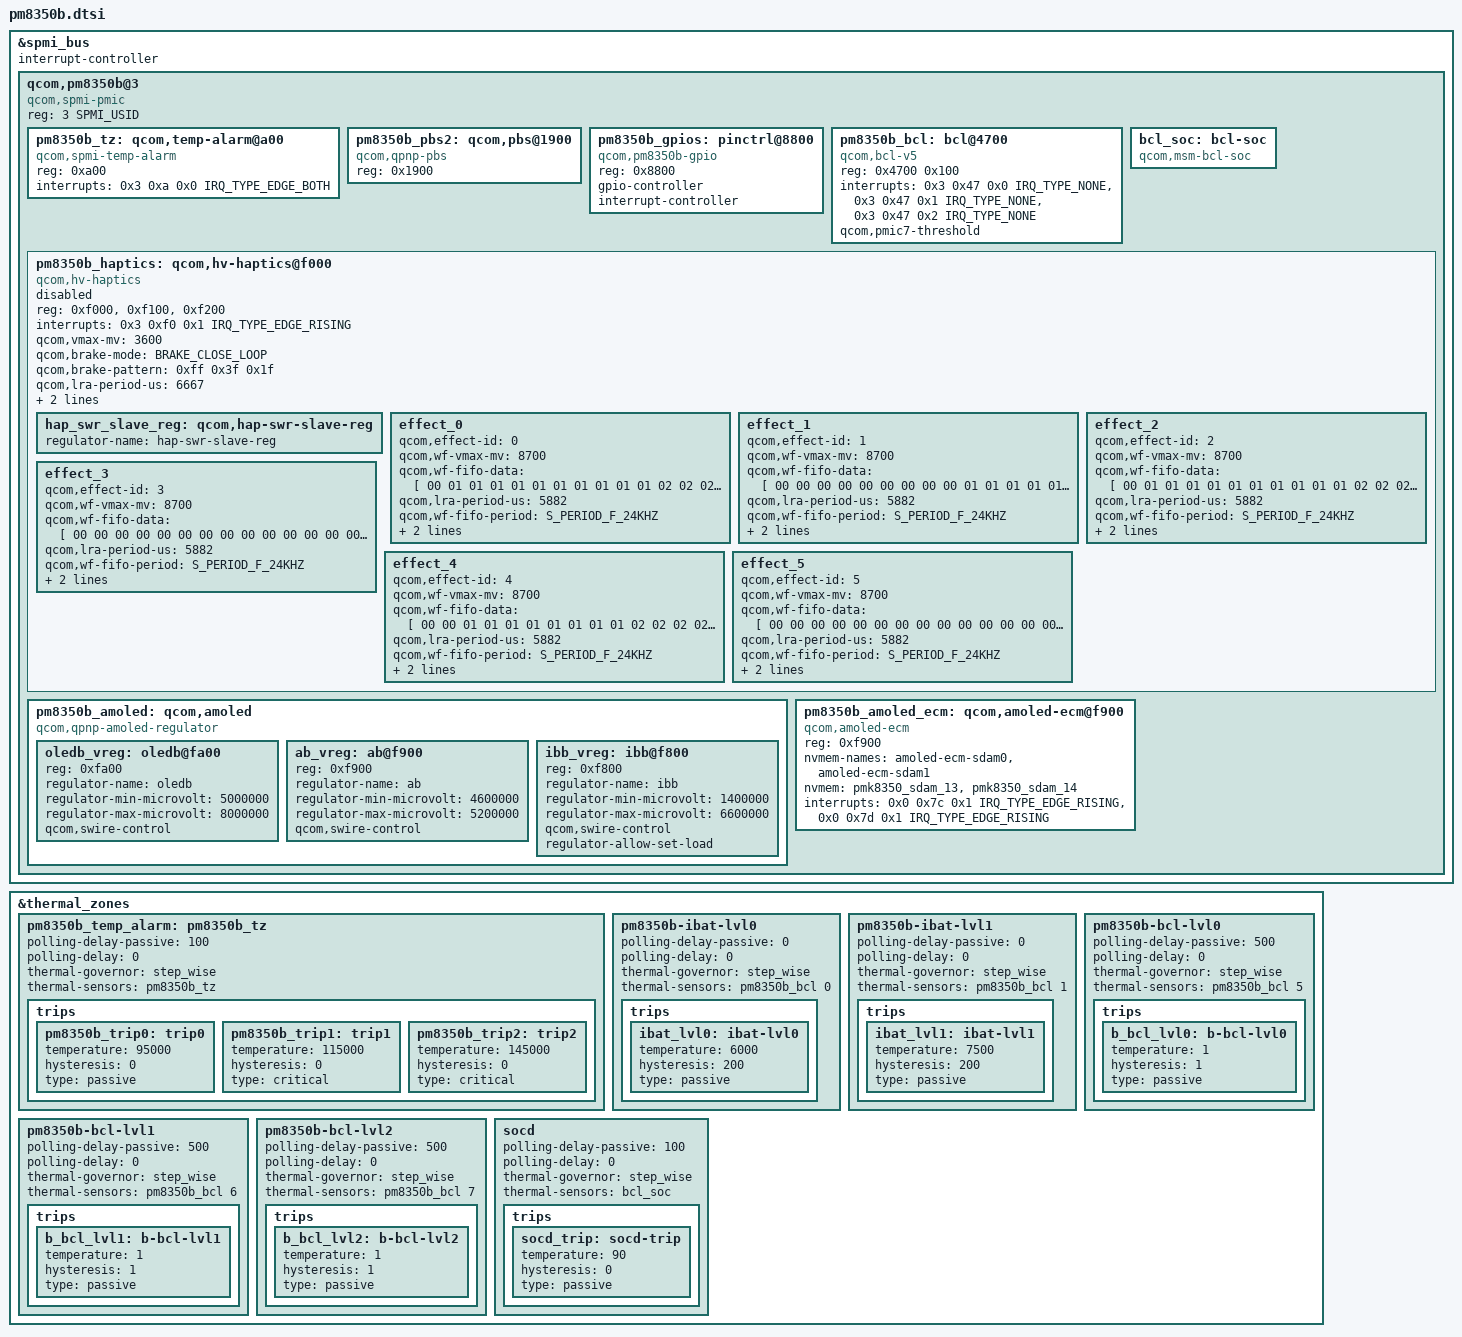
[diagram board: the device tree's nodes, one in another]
#include <dt-bindings/interrupt-controller/irq.h>
#include <dt-bindings/spmi/spmi.h>
#include <dt-bindings/input/qcom,hv-haptics.h>

&spmi_bus {
	#address-cells = <2>;
	#size-cells = <0>;
	interrupt-controller;
	#interrupt-cells = <4>;

	qcom,pm8350b@3 {
		compatible = "qcom,spmi-pmic";
		reg = <3 SPMI_USID>;
		#address-cells = <1>;
		#size-cells = <0>;

		pm8350b_tz: qcom,temp-alarm@a00 {
			compatible = "qcom,spmi-temp-alarm";
			reg = <0xa00>;
			interrupts = <0x3 0xa 0x0 IRQ_TYPE_EDGE_BOTH>;
			#thermal-sensor-cells = <0>;
		};

		pm8350b_pbs2: qcom,pbs@1900 {
			compatible = "qcom,qpnp-pbs";
			reg = <0x1900>;
		};

		pm8350b_gpios: pinctrl@8800 {
			compatible = "qcom,pm8350b-gpio";
			reg = <0x8800>;
			gpio-controller;
			#gpio-cells = <2>;
			interrupt-controller;
			#interrupt-cells = <2>;
		};

		pm8350b_bcl: bcl@4700 {
			compatible = "qcom,bcl-v5";
			reg = <0x4700 0x100>;
			interrupts = <0x3 0x47 0x0 IRQ_TYPE_NONE>,
					<0x3 0x47 0x1 IRQ_TYPE_NONE>,
					<0x3 0x47 0x2 IRQ_TYPE_NONE>;
			interrupt-names = "bcl-lvl0",
						"bcl-lvl1",
						"bcl-lvl2";
			qcom,pmic7-threshold;
			#thermal-sensor-cells = <1>;
		};

		bcl_soc:bcl-soc {
			compatible = "qcom,msm-bcl-soc";
			#thermal-sensor-cells = <0>;
		};

		pm8350b_haptics: qcom,hv-haptics@f000 {
			compatible = "qcom,hv-haptics";
			reg = <0xf000>, <0xf100>, <0xf200>;
			interrupts = <0x3 0xf0 0x1 IRQ_TYPE_EDGE_RISING>;
			interrupt-names = "fifo-empty";
			qcom,vmax-mv = <3600>;
			qcom,brake-mode = <BRAKE_CLOSE_LOOP>;
			qcom,brake-pattern = /bits/ 8 <0xff 0x3f 0x1f>;
			qcom,lra-period-us = <6667>;
			qcom,drv-sig-shape = <WF_SINE>;
			qcom,brake-sig-shape = <WF_SINE>;
			status = "disabled";

			hap_swr_slave_reg: qcom,hap-swr-slave-reg {
				regulator-name = "hap-swr-slave-reg";
			};

			effect_0 {
				/* CLICK */
				qcom,effect-id = <0>;
				qcom,wf-vmax-mv = <8700>;
				qcom,wf-fifo-data = [
								    00 01 01 01 01 01 01 01
				                                    01 01 01 02 02 02 02 02
				                                    03 03 03 04 04 04 05 05
				                                    05 06 06 07 08 08 09 0a
				                                    0b 0c 0d 0e 0f 10 11 13
				                                    14 16 18 1a 1c 1e 21 24
				                                    27 2a 2d 31 35 39 3e 43
				                                    49 4f 55 5c 64 6b 71 76
				                                    7a 7d 7f 7f 7f 7f 7d 7b
				                                    78 74 70 6b 65 60 59 53
				                                    4c 45 3d 36 2e 26 1e 16
				                                    0f 07 00 f8 f0 e9 e1 da
				                                    d4 cd c6 c0 ba b3 ae a9
				                                    a6 a4 a3 a3 a5 a8 ab b0
				                                    b6 bc c3 cb d4 dd e6 f0
				                                    fa 04 0f 19 24 2e 38 41
				                                    4a 53 5b 62 69 6e 73 77
				                                    79 7b 7b 7a 78 74 6f 68
				                                    60 59 52 4b 44 3d 36 30
				                                    29 22 1b 14 0e 07 00 fa
				                                    f3 ed e6 e0 da d4 cf ca
				                                    c5 c0 bc b8 b5 b2 af ad
				                                    ac ac ac ac ae b0 b3 b6
				                                    bb c0 c5 ca ce d2 d6 d9
				                                    dc df e2 e4 e7 e9 ea ec
				                                    ee ef f1 f2 f3 f4 f5 f6
				                                    f7 f7 f8 f9 f9 fa fa fb
				                                    fb fb fc fc fc fd fd fd
				                                    fd fd fd fe fe fe fe fe
				                                    fe fe fe fe fe fe fe 00
				                                    00 00 00 00 00 00 00 00
				                                    00 00 00 00 00 00 00 00
				                                    00 00 00 00 00 00 00 00 ];
				qcom,lra-period-us = <5882>;
				qcom,wf-fifo-period = <S_PERIOD_F_24KHZ>;
				qcom,wf-brake-disable;
				qcom,wf-auto-res-disable;
			};

			effect_1 {
				/* DOUBLE_CLICK */
				qcom,effect-id = <1>;
				qcom,wf-vmax-mv = <8700>;
				qcom,wf-fifo-data = [
								    00 00 00 00 00 00 00 00
				                                    00 01 01 01 01 01 01 01
				                                    01 01 02 02 02 02 02 03
				                                    03 03 03 04 04 05 05 05
				                                    06 06 07 08 08 09 0a 0b
				                                    0b 0c 0d 0f 10 11 12 13
				                                    13 13 13 13 13 12 12 11
				                                    10 0e 0d 0c 0a 08 06 04
				                                    02 00 fd fb f8 f5 f2 ef
				                                    ec e9 e5 e2 de da d6 d2
				                                    cd c9 c4 be b9 b3 ad a8
				                                    a5 a3 a2 a3 a4 a7 ab af
				                                    b5 bc c3 cb d4 dd e7 f1
				                                    fb 06 10 1b 26 30 3a 44
				                                    4d 56 5e 66 6c 72 77 7b
				                                    7e 7f 7f 7f 7c 78 73 6c
				                                    65 5e 57 50 49 42 3b 34
				                                    2e 27 20 1a 13 0d 07 00
				                                    fa f4 ee e9 e4 de da d5
				                                    d1 ce cb c8 c6 c4 c4 c3
				                                    c4 c5 c8 cb cf d4 da e1
				                                    e9 f2 fb 02 0a 10 16 1c
				                                    21 25 29 2c 30 32 35 37
				                                    38 3a 3b 3c 3d 3d 3d 3e
				                                    3d 3d 3d 3c 3c 3b 3a 39
				                                    38 37 36 35 33 32 31 2f
				                                    2e 2c 2b 29 28 26 25 23
				                                    22 20 1f 1e 1c 1b 19 18
				                                    17 15 14 13 12 11 0f 0e
				                                    0d 0c 0b 0a 09 08 07 07
				                                    06 05 04 04 03 02 02 01
				                                    00 00 00 00 00 fe fe fd
				                                    fd fd fc fc fc fc fb fb
				                                    fb fb fb fb fb fb fa fa
				                                    fa fa fa fa fa fa fa fa
				                                    fa fa fb fb fb fb fb fb
				                                    fb fb fb fb fb fb fc fc
				                                    fc fc fc fc fc fc fc fd
				                                    fd fd fd fd fd fd fd fd
				                                    fd fe fe fe fe fe fe fe
				                                    fe fe fe fe 00 00 00 00 ];
				qcom,lra-period-us = <5882>;
				qcom,wf-fifo-period = <S_PERIOD_F_24KHZ>;
				qcom,wf-brake-disable;
				qcom,wf-auto-res-disable;
			};

			effect_2 {
				/* TICK */
				qcom,effect-id = <2>;
				qcom,wf-vmax-mv = <8700>;
				qcom,wf-fifo-data = [
								    00 01 01 01 01 01 01 01
				                                    01 01 01 02 02 02 02 02
				                                    03 03 03 04 04 04 05 05
				                                    05 06 06 07 08 08 09 0a
				                                    0b 0c 0d 0e 0f 10 11 13
				                                    14 16 18 1a 1c 1e 21 24
				                                    27 2a 2d 31 35 39 3e 43
				                                    49 4f 55 5c 64 6b 71 76
				                                    7a 7d 7f 7f 7f 7f 7d 7b
				                                    78 74 70 6b 65 60 59 53
				                                    4c 45 3d 36 2e 26 1e 16
				                                    0f 07 00 f8 f0 e9 e1 da
				                                    d4 cd c6 c0 ba b3 ae a9
				                                    a6 a4 a3 a3 a5 a8 ab b0
				                                    b6 bc c3 cb d4 dd e6 f0
				                                    fa 04 0f 19 24 2e 38 41
				                                    4a 53 5b 62 69 6e 73 77
				                                    79 7b 7b 7a 78 74 6f 68
				                                    60 59 52 4b 44 3d 36 30
				                                    29 22 1b 14 0e 07 00 fa
				                                    f3 ed e6 e0 da d4 cf ca
				                                    c5 c0 bc b8 b5 b2 af ad
				                                    ac ac ac ac ae b0 b3 b6
				                                    bb c0 c5 ca ce d2 d6 d9
				                                    dc df e2 e4 e7 e9 ea ec
				                                    ee ef f1 f2 f3 f4 f5 f6
				                                    f7 f7 f8 f9 f9 fa fa fb
				                                    fb fb fc fc fc fd fd fd
				                                    fd fd fd fe fe fe fe fe
				                                    fe fe fe fe fe fe fe 00
				                                    00 00 00 00 00 00 00 00
				                                    00 00 00 00 00 00 00 00
				                                    00 00 00 00 00 00 00 00 ];
				qcom,lra-period-us = <5882>;
				qcom,wf-fifo-period = <S_PERIOD_F_24KHZ>;
				qcom,wf-brake-disable;
				qcom,wf-auto-res-disable;
			};

			effect_3 {
				/* THUD */
				qcom,effect-id = <3>;
				qcom,wf-vmax-mv = <8700>;
				qcom,wf-fifo-data = [
								    00 00 00 00 00 00 00 00
				                                    00 00 00 00 00 00 00 00
				                                    00 00 00 00 00 00 00 00
				                                    00 00 00 00 01 01 01 01
				                                    01 01 02 02 02 03 03 04
				                                    04 05 06 07 08 09 0a 0c
				                                    0e 10 12 14 17 1b 1e 23
				                                    28 2d 34 3b 43 4b 52 58
				                                    5d 61 64 66 68 6a 6a 6b
				                                    6a 6a 69 68 66 65 62 60
				                                    5e 5b 58 56 53 4f 4c 49
				                                    45 42 3e 3b 37 33 2f 2c
				                                    28 24 1f 1b 17 12 0d 08
				                                    03 fc f6 ef e8 e0 d7 cd
				                                    c2 b7 ad a5 9f 9a 96 93
				                                    92 91 91 93 94 97 9a 9e
				                                    a2 a7 ac b1 b7 bd c4 ca
				                                    d1 d8 df e6 ee f5 fc 04
				                                    0b 12 19 20 26 2d 33 39
				                                    3f 45 4a 4f 54 59 5e 62
				                                    66 6a 6e 72 75 79 7c 7e
				                                    7f 7f 7f 7e 7c 7a 77 73
				                                    6f 6a 65 5f 59 53 4c 45
				                                    3e 37 2f 27 1f 17 0f 07
				                                    fe f6 ee e6 df d7 d0 c9
				                                    c2 bc b6 b1 ac a7 a3 a0
				                                    9d 9b 99 99 99 9a 9c 9e
				                                    a2 a8 ad b2 b7 bc c1 c5
				                                    ca cf d3 d8 dd e2 e7 ec
				                                    f2 f7 fd 03 09 0f 14 1a
				                                    20 26 2c 32 37 3d 42 48
				                                    4d 52 57 5b 5f 63 67 6a
				                                    6c 6e 70 71 71 71 6f 6d
				                                    6a 66 61 5a 52 49 3f 35
				                                    2d 26 1f 1a 14 0f 0b 07
				                                    03 00 fb f8 f5 f3 f0 ed
				                                    eb e9 e6 e4 e2 e0 de dc
				                                    da d8 d6 d5 d3 d1 d0 cf
				                                    cd cc cb cb ca ca c9 c9
				                                    ca ca cb cc cd cf d2 d4
				                                    d8 dc e0 e4 e8 eb ee f0
				                                    f2 f4 f5 f7 f8 f9 fa fb
				                                    fb fc fd fd fd fe fe fe
				                                    fe 00 00 00 00 00 00 00
				                                    00 00 00 00 00 00 00 00
				                                    00 00 00 00 00 00 00 00
				                                    00 00 00 00 00 00 00 00 ];
				qcom,lra-period-us = <5882>;
				qcom,wf-fifo-period = <S_PERIOD_F_24KHZ>;
				qcom,wf-brake-disable;
				qcom,wf-auto-res-disable;
			};

			effect_4 {
				/* POP */
				qcom,effect-id = <4>;
				qcom,wf-vmax-mv = <8700>;
				qcom,wf-fifo-data = [
								    00 00 01 01 01 01 01 01
				                                    01 01 02 02 02 02 02 02
				                                    03 03 03 04 04 04 05 05
				                                    06 06 07 07 08 08 09 0a
				                                    0b 0c 0d 0e 0f 10 12 13
				                                    15 17 18 1b 1d 1f 22 24
				                                    27 2b 2e 32 36 3b 40 45
				                                    4a 51 57 5e 65 6b 70 75
				                                    78 7b 7d 7f 7f 7f 7f 7e
				                                    7d 7b 78 76 72 6f 6b 67
				                                    63 5e 59 54 4f 4a 44 3f
				                                    39 33 2e 28 22 1d 17 11
				                                    0c 06 01 fb f6 f0 eb e5
				                                    e0 da d5 cf cb c8 c6 c4
				                                    c3 c4 c5 c6 c9 cc cf d3
				                                    d8 dd e3 e9 ef f5 fc 03
				                                    0a 11 18 1f 26 2d 34 3a
				                                    40 46 4b 50 55 59 5c 5e
				                                    60 61 62 61 60 5e 5b 56
				                                    51 4b 44 3d 37 31 2b 25
				                                    20 1a 15 0f 0a 05 00 fa
				                                    f5 f1 ec e7 e2 de d9 d5
				                                    d0 cc c8 c4 c1 bd ba b7
				                                    b5 b2 b0 af ad ac ac ac
				                                    ac ad ae af b2 b5 b8 bc
				                                    c1 c6 ca cf d2 d6 d9 dc
				                                    df e2 e4 e6 e8 ea ec ed
				                                    ef f0 f1 f2 f3 f4 f5 f6
				                                    f7 f7 f8 f9 f9 f9 fa fa
				                                    fb fb fb fc fc fc fc fc
				                                    fd fd fd fd fd fd fd fe
				                                    fe fe fe fe fe fe fe fe
				                                    fe fe fe fe fe fe fe fe
				                                    fe 00 00 00 00 00 00 00
				                                    00 00 00 00 00 00 00 00 ];
				qcom,lra-period-us = <5882>;
				qcom,wf-fifo-period = <S_PERIOD_F_24KHZ>;
				qcom,wf-brake-disable;
				qcom,wf-auto-res-disable;
			};

			effect_5 {
				/* HEAVY CLICK */
				qcom,effect-id = <5>;
				qcom,wf-vmax-mv = <8700>;
				qcom,wf-fifo-data = [
								    00 00 00 00 00 00 00 00
				                                    00 00 00 00 00 00 00 00
				                                    00 00 00 00 00 00 00 00
				                                    00 00 00 00 01 01 01 01
				                                    01 01 02 02 02 03 03 04
				                                    04 05 06 07 08 09 0a 0c
				                                    0e 10 12 14 17 1b 1e 23
				                                    28 2d 34 3b 43 4b 52 58
				                                    5d 61 64 66 68 6a 6a 6b
				                                    6a 6a 69 68 66 65 62 60
				                                    5e 5b 58 56 53 4f 4c 49
				                                    45 42 3e 3b 37 33 2f 2c
				                                    28 24 1f 1b 17 12 0d 08
				                                    03 fc f6 ef e8 e0 d7 cd
				                                    c2 b7 ad a5 9f 9a 96 93
				                                    92 91 91 93 94 97 9a 9e
				                                    a2 a7 ac b1 b7 bd c4 ca
				                                    d1 d8 df e6 ee f5 fc 04
				                                    0b 12 19 20 26 2d 33 39
				                                    3f 45 4a 4f 54 59 5e 62
				                                    66 6a 6e 72 75 79 7c 7e
				                                    7f 7f 7f 7e 7c 7a 77 73
				                                    6f 6a 65 5f 59 53 4c 45
				                                    3e 37 2f 27 1f 17 0f 07
				                                    fe f6 ee e6 df d7 d0 c9
				                                    c2 bc b6 b1 ac a7 a3 a0
				                                    9d 9b 99 99 99 9a 9c 9e
				                                    a2 a8 ad b2 b7 bc c1 c5
				                                    ca cf d3 d8 dd e2 e7 ec
				                                    f2 f7 fd 03 09 0f 14 1a
				                                    20 26 2c 32 37 3d 42 48
				                                    4d 52 57 5b 5f 63 67 6a
				                                    6c 6e 70 71 71 71 6f 6d
				                                    6a 66 61 5a 52 49 3f 35
				                                    2d 26 1f 1a 14 0f 0b 07
				                                    03 00 fb f8 f5 f3 f0 ed
				                                    eb e9 e6 e4 e2 e0 de dc
				                                    da d8 d6 d5 d3 d1 d0 cf
				                                    cd cc cb cb ca ca c9 c9
				                                    ca ca cb cc cd cf d2 d4
				                                    d8 dc e0 e4 e8 eb ee f0
				                                    f2 f4 f5 f7 f8 f9 fa fb
				                                    fb fc fd fd fd fe fe fe
				                                    fe 00 00 00 00 00 00 00
				                                    00 00 00 00 00 00 00 00
				                                    00 00 00 00 00 00 00 00
				                                    00 00 00 00 00 00 00 00 ];
				qcom,lra-period-us = <5882>;
				qcom,wf-fifo-period = <S_PERIOD_F_24KHZ>;
				qcom,wf-brake-disable;
				qcom,wf-auto-res-disable;
			};
		};

		pm8350b_amoled: qcom,amoled {
			compatible = "qcom,qpnp-amoled-regulator";
			#address-cells = <1>;
			#size-cells = <0>;

			oledb_vreg: oledb@fa00 {
				reg = <0xfa00>;
				reg-names = "oledb_base";
				regulator-name = "oledb";
				regulator-min-microvolt = <5000000>;
				regulator-max-microvolt = <8000000>;
				qcom,swire-control;
			};

			ab_vreg: ab@f900 {
				reg = <0xf900>;
				reg-names = "ab_base";
				regulator-name = "ab";
				regulator-min-microvolt = <4600000>;
				regulator-max-microvolt = <5200000>;
				qcom,swire-control;
			};

			ibb_vreg: ibb@f800 {
				reg = <0xf800>;
				reg-names = "ibb_base";
				regulator-name = "ibb";
				regulator-min-microvolt = <1400000>;
				regulator-max-microvolt = <6600000>;
				qcom,swire-control;
				regulator-allow-set-load;
			};
		};

		pm8350b_amoled_ecm: qcom,amoled-ecm@f900 {
			compatible = "qcom,amoled-ecm";
			reg = <0xf900>;
			nvmem-names = "amoled-ecm-sdam0", "amoled-ecm-sdam1";
			nvmem = <&pmk8350_sdam_13>, <&pmk8350_sdam_14>;
			interrupt-names = "ecm-sdam0", "ecm-sdam1";
			interrupts = <0x0 0x7c 0x1 IRQ_TYPE_EDGE_RISING>,
				     <0x0 0x7d 0x1 IRQ_TYPE_EDGE_RISING>;
		};
	};
};

&thermal_zones {
	pm8350b_temp_alarm: pm8350b_tz {
		polling-delay-passive = <100>;
		polling-delay = <0>;
		thermal-governor = "step_wise";
		thermal-sensors = <&pm8350b_tz>;

		trips {
			pm8350b_trip0: trip0 {
				temperature = <95000>;
				hysteresis = <0>;
				type = "passive";
			};

			pm8350b_trip1: trip1 {
				temperature = <115000>;
				hysteresis = <0>;
				type = "critical";
			};

			pm8350b_trip2: trip2 {
				temperature = <145000>;
				hysteresis = <0>;
				type = "critical";
			};
		};
	};

	pm8350b-ibat-lvl0 {
		polling-delay-passive = <0>;
		polling-delay = <0>;
		thermal-governor = "step_wise";
		thermal-sensors = <&pm8350b_bcl 0>;

		trips {
			ibat_lvl0:ibat-lvl0 {
				temperature = <6000>;
				hysteresis = <200>;
				type = "passive";
			};
		};
	};

	pm8350b-ibat-lvl1 {
		polling-delay-passive = <0>;
		polling-delay = <0>;
		thermal-governor = "step_wise";
		thermal-sensors = <&pm8350b_bcl 1>;

		trips {
			ibat_lvl1:ibat-lvl1 {
				temperature = <7500>;
				hysteresis = <200>;
				type = "passive";
			};
		};
	};

	pm8350b-bcl-lvl0 {
		polling-delay-passive = <500>;
		polling-delay = <0>;
		thermal-governor = "step_wise";
		thermal-sensors = <&pm8350b_bcl 5>;

		trips {
			b_bcl_lvl0: b-bcl-lvl0 {
				temperature = <1>;
				hysteresis = <1>;
				type = "passive";
			};
		};
	};

	pm8350b-bcl-lvl1 {
		polling-delay-passive = <500>;
		polling-delay = <0>;
		thermal-governor = "step_wise";
		thermal-sensors = <&pm8350b_bcl 6>;

		trips {
			b_bcl_lvl1: b-bcl-lvl1 {
				temperature = <1>;
				hysteresis = <1>;
				type = "passive";
			};
		};
	};

	pm8350b-bcl-lvl2 {
		polling-delay-passive = <500>;
		polling-delay = <0>;
		thermal-governor = "step_wise";
		thermal-sensors = <&pm8350b_bcl 7>;

		trips {
			b_bcl_lvl2: b-bcl-lvl2 {
				temperature = <1>;
				hysteresis = <1>;
				type = "passive";
			};
		};
	};

	socd {
		polling-delay-passive = <100>;
		polling-delay = <0>;
		thermal-governor = "step_wise";
		thermal-sensors = <&bcl_soc>;

		trips {
			socd_trip:socd-trip {
				temperature = <90>;
				hysteresis = <0>;
				type = "passive";
			};
		};
	};
};
